AUTOSAR XML (schema 4-0-3)
package /ComponentTypes
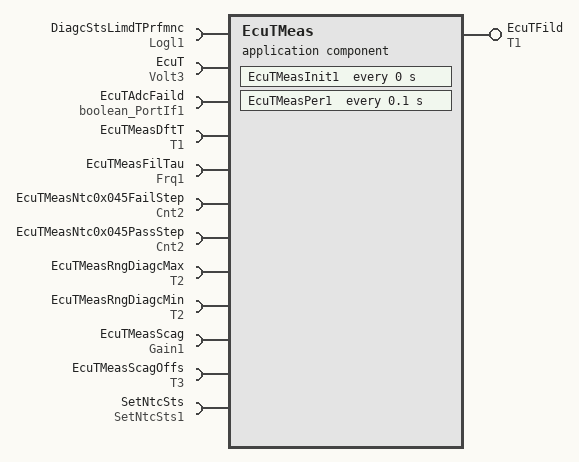
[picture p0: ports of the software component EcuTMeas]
  application sw component type EcuTMeas
    provide port EcuTFild: nonqueued-sender-com-spec{data-element=Val, init-value=25}, provided-interface=T1
    12 x require port:
      DiagcStsLimdTPrfmnc: nonqueued-receiver-com-spec{data-element=Logl, filter=data-filter-type=ALWAYS, init-value=0}, required-interface=Logl1
      EcuT: nonqueued-receiver-com-spec{data-element=Val, filter=data-filter-type=ALWAYS, init-value=0}, required-interface=Volt3
      EcuTAdcFaild: nonqueued-receiver-com-spec{data-element=Logl, filter=data-filter-type=ALWAYS, init-value=0}, required-interface=boolean_PortIf1
      EcuTMeasDftT: parameter-require-com-spec{init-value=60, parameter=Val}, required-interface=T1
      EcuTMeasFilTau: parameter-require-com-spec{init-value=0.5, parameter=Val}, required-interface=Frq1
      EcuTMeasNtc0x045FailStep: parameter-require-com-spec{init-value=3000, parameter=Val}, required-interface=Cnt2
      EcuTMeasNtc0x045PassStep: parameter-require-com-spec{init-value=3000, parameter=Val}, required-interface=Cnt2
      EcuTMeasRngDiagcMax: parameter-require-com-spec{init-value=145, parameter=Val}, required-interface=T2
      EcuTMeasRngDiagcMin: parameter-require-com-spec{init-value=-45, parameter=Val}, required-interface=T2
      EcuTMeasScag: parameter-require-com-spec{init-value=100, parameter=Val}, required-interface=Gain1
      EcuTMeasScagOffs: parameter-require-com-spec{init-value=-50, parameter=Val}, required-interface=T3
      SetNtcSts: required-interface=SetNtcSts1
    behavior EcuTMeas_InternalBehavior: data-type-mapping=Nexteer
      ar-typed-per-instance-memorys:
        data EcuTMeasFilStVarPrev: sw-calibration-access=READ-ONLY, type=FilLpRec1
      timing event EcuTMeas_InitEvent: start-on-event=EcuTMeasInit1, period=0
      timing event TMT_EcuTMeasPer1: start-on-event=EcuTMeasPer1, period=0.1
      runnable EcuTMeasInit1
        data-receive-point-by-arguments:
          access REC_EcuT_Val: accessed-variable=EcuT.Val
        sync call SC_SetNtcSts_Oper: operation=SetNtcSts.Oper, timeout=0
      runnable EcuTMeasPer1
        data-receive-point-by-arguments:
          access REC_DiagcStsLimdTPrfmnc_Logl: accessed-variable=DiagcStsLimdTPrfmnc.Logl
          access REC_EcuT_Val: accessed-variable=EcuT.Val
          access REC_EcuTAdcFaild_Logl: accessed-variable=EcuTAdcFaild.Logl
        data-send-points:
          access SEND_EcuTFild_Val: accessed-variable=EcuTFild.Val
        sync call SC_SetNtcSts_Oper: operation=SetNtcSts.Oper, timeout=0
  swc implementation EcuTMeas_Implementation: behavior=EcuTMeas_InternalBehavior
    code-descriptors:
      code Default: artifact-descriptors=autosar-engineering-object={short-label=Default, category=SWSRC}
